AUTOSAR XML (schema 4-2-2)
package /UAES/ASW
  swc implementation Implementation: programming-language=C, sw-version=1.226.1, used-code-generator=Embedded Coder 7.1 (R2018b) 24-May-2018, vendor-id=0, behavior=InternalBehavior
    code-descriptors:
      code Code
        artifact-descriptors:
          short-label=Win_SLC_c, category=SWSRC
          short-label=Win_SLC_h, category=SWHDR
          short-label=rtwtypes_h, category=SWHDR
    resource consumption RsrcCons_Win_SLC
package /UAES/ASW/SwComponentTypes
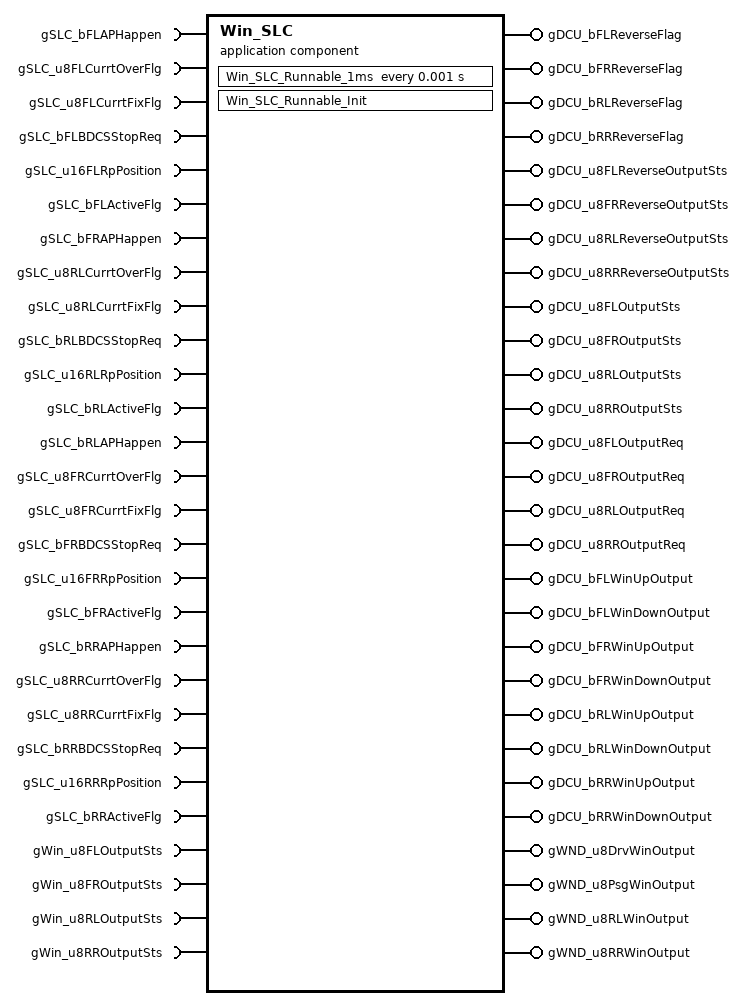
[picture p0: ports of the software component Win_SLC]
  application sw component type Win_SLC
    28 x require port:
      gSLC_bFLAPHappen: nonqueued-receiver-com-spec{data-element=gSLC_bFLAPHappen/Val, init-value=0}, required-interface=gSLC_bFLAPHappen
      gSLC_u8FLCurrtOverFlg: nonqueued-receiver-com-spec{data-element=gSLC_u8FLCurrtOverFlg/Val, init-value=0}, required-interface=gSLC_u8FLCurrtOverFlg
      gSLC_u8FLCurrtFixFlg: nonqueued-receiver-com-spec{data-element=gSLC_u8FLCurrtFixFlg/Val, init-value=0}, required-interface=gSLC_u8FLCurrtFixFlg
      gSLC_bFLBDCSStopReq: nonqueued-receiver-com-spec{data-element=gSLC_bFLBDCSStopReq/Val, init-value=0}, required-interface=gSLC_bFLBDCSStopReq
      gSLC_u16FLRpPosition: nonqueued-receiver-com-spec{data-element=gSLC_u16FLRpPosition/Val, init-value=0}, required-interface=gSLC_u16FLRpPosition
      gSLC_bFLActiveFlg: nonqueued-receiver-com-spec{data-element=gSLC_bFLActiveFlg/Val, init-value=0}, required-interface=gSLC_bFLActiveFlg
      gSLC_bFRAPHappen: nonqueued-receiver-com-spec{data-element=gSLC_bFRAPHappen/Val, init-value=0}, required-interface=gSLC_bFRAPHappen
      gSLC_u8RLCurrtOverFlg: nonqueued-receiver-com-spec{data-element=gSLC_u8RLCurrtOverFlg/Val, init-value=0}, required-interface=gSLC_u8RLCurrtOverFlg
      gSLC_u8RLCurrtFixFlg: nonqueued-receiver-com-spec{data-element=gSLC_u8RLCurrtFixFlg/Val, init-value=0}, required-interface=gSLC_u8RLCurrtFixFlg
      gSLC_bRLBDCSStopReq: nonqueued-receiver-com-spec{data-element=gSLC_bRLBDCSStopReq/Val, init-value=0}, required-interface=gSLC_bRLBDCSStopReq
      gSLC_u16RLRpPosition: nonqueued-receiver-com-spec{data-element=gSLC_u16RLRpPosition/Val, init-value=0}, required-interface=gSLC_u16RLRpPosition
      gSLC_bRLActiveFlg: nonqueued-receiver-com-spec{data-element=gSLC_bRLActiveFlg/Val, init-value=0}, required-interface=gSLC_bRLActiveFlg
      gSLC_bRLAPHappen: nonqueued-receiver-com-spec{data-element=gSLC_bRLAPHappen/Val, init-value=0}, required-interface=gSLC_bRLAPHappen
      gSLC_u8FRCurrtOverFlg: nonqueued-receiver-com-spec{data-element=gSLC_u8FRCurrtOverFlg/Val, init-value=0}, required-interface=gSLC_u8FRCurrtOverFlg
      gSLC_u8FRCurrtFixFlg: nonqueued-receiver-com-spec{data-element=gSLC_u8FRCurrtFixFlg/Val, init-value=0}, required-interface=gSLC_u8FRCurrtFixFlg
      gSLC_bFRBDCSStopReq: nonqueued-receiver-com-spec{data-element=gSLC_bFRBDCSStopReq/Val, init-value=0}, required-interface=gSLC_bFRBDCSStopReq
      gSLC_u16FRRpPosition: nonqueued-receiver-com-spec{data-element=gSLC_u16FRRpPosition/Val, init-value=0}, required-interface=gSLC_u16FRRpPosition
      gSLC_bFRActiveFlg: nonqueued-receiver-com-spec{data-element=gSLC_bFRActiveFlg/Val, init-value=0}, required-interface=gSLC_bFRActiveFlg
      gSLC_bRRAPHappen: nonqueued-receiver-com-spec{data-element=gSLC_bRRAPHappen/Val, init-value=0}, required-interface=gSLC_bRRAPHappen
      gSLC_u8RRCurrtOverFlg: nonqueued-receiver-com-spec{data-element=gSLC_u8RRCurrtOverFlg/Val, init-value=0}, required-interface=gSLC_u8RRCurrtOverFlg
      gSLC_u8RRCurrtFixFlg: nonqueued-receiver-com-spec{data-element=gSLC_u8RRCurrtFixFlg/Val, init-value=0}, required-interface=gSLC_u8RRCurrtFixFlg
      gSLC_bRRBDCSStopReq: nonqueued-receiver-com-spec{data-element=gSLC_bRRBDCSStopReq/Val, init-value=0}, required-interface=gSLC_bRRBDCSStopReq
      gSLC_u16RRRpPosition: nonqueued-receiver-com-spec{data-element=gSLC_u16RRRpPosition/Val, init-value=0}, required-interface=gSLC_u16RRRpPosition
      gSLC_bRRActiveFlg: nonqueued-receiver-com-spec{data-element=gSLC_bRRActiveFlg/Val, init-value=0}, required-interface=gSLC_bRRActiveFlg
      gWin_u8FLOutputSts: nonqueued-receiver-com-spec{data-element=gWin_u8FLOutputSts/Val, init-value=0}, required-interface=gWin_u8FLOutputSts
      gWin_u8FROutputSts: nonqueued-receiver-com-spec{data-element=gWin_u8FROutputSts/Val, init-value=0}, required-interface=gWin_u8FROutputSts
      gWin_u8RLOutputSts: nonqueued-receiver-com-spec{data-element=gWin_u8RLOutputSts/Val, init-value=0}, required-interface=gWin_u8RLOutputSts
      gWin_u8RROutputSts: nonqueued-receiver-com-spec{data-element=gWin_u8RROutputSts/Val, init-value=0}, required-interface=gWin_u8RROutputSts
    28 x provide port:
      gDCU_bFLReverseFlag: nonqueued-sender-com-spec{data-element=gDCU_bFLReverseFlag/Val, init-value=0}, provided-interface=gDCU_bFLReverseFlag
      gDCU_bFRReverseFlag: nonqueued-sender-com-spec{data-element=gDCU_bFRReverseFlag/Val, init-value=0}, provided-interface=gDCU_bFRReverseFlag
      gDCU_bRLReverseFlag: nonqueued-sender-com-spec{data-element=gDCU_bRLReverseFlag/Val, init-value=0}, provided-interface=gDCU_bRLReverseFlag
      gDCU_bRRReverseFlag: nonqueued-sender-com-spec{data-element=gDCU_bRRReverseFlag/Val, init-value=0}, provided-interface=gDCU_bRRReverseFlag
      gDCU_u8FLReverseOutputSts: nonqueued-sender-com-spec{data-element=gDCU_u8FLReverseOutputSts/Val, init-value=0}, provided-interface=gDCU_u8FLReverseOutputSts
      gDCU_u8FRReverseOutputSts: nonqueued-sender-com-spec{data-element=gDCU_u8FRReverseOutputSts/Val, init-value=0}, provided-interface=gDCU_u8FRReverseOutputSts
      gDCU_u8RLReverseOutputSts: nonqueued-sender-com-spec{data-element=gDCU_u8RLReverseOutputSts/Val, init-value=0}, provided-interface=gDCU_u8RLReverseOutputSts
      gDCU_u8RRReverseOutputSts: nonqueued-sender-com-spec{data-element=gDCU_u8RRReverseOutputSts/Val, init-value=0}, provided-interface=gDCU_u8RRReverseOutputSts
      gDCU_u8FLOutputSts: nonqueued-sender-com-spec{data-element=gDCU_u8FLOutputSts/Val, init-value=0}, provided-interface=gDCU_u8FLOutputSts
      gDCU_u8FROutputSts: nonqueued-sender-com-spec{data-element=gDCU_u8FROutputSts/Val, init-value=0}, provided-interface=gDCU_u8FROutputSts
      gDCU_u8RLOutputSts: nonqueued-sender-com-spec{data-element=gDCU_u8RLOutputSts/Val, init-value=0}, provided-interface=gDCU_u8RLOutputSts
      gDCU_u8RROutputSts: nonqueued-sender-com-spec{data-element=gDCU_u8RROutputSts/Val, init-value=0}, provided-interface=gDCU_u8RROutputSts
      gDCU_u8FLOutputReq: nonqueued-sender-com-spec{data-element=gDCU_u8FLOutputReq/Val, init-value=0}, provided-interface=gDCU_u8FLOutputReq
      gDCU_u8FROutputReq: nonqueued-sender-com-spec{data-element=gDCU_u8FROutputReq/Val, init-value=0}, provided-interface=gDCU_u8FROutputReq
      gDCU_u8RLOutputReq: nonqueued-sender-com-spec{data-element=gDCU_u8RLOutputReq/Val, init-value=0}, provided-interface=gDCU_u8RLOutputReq
      gDCU_u8RROutputReq: nonqueued-sender-com-spec{data-element=gDCU_u8RROutputReq/Val, init-value=0}, provided-interface=gDCU_u8RROutputReq
      gDCU_bFLWinUpOutput: nonqueued-sender-com-spec{data-element=gDCU_bFLWinUpOutput/Val, init-value=0}, provided-interface=gDCU_bFLWinUpOutput
      gDCU_bFLWinDownOutput: nonqueued-sender-com-spec{data-element=gDCU_bFLWinDownOutput/Val, init-value=0}, provided-interface=gDCU_bFLWinDownOutput
      gDCU_bFRWinUpOutput: nonqueued-sender-com-spec{data-element=gDCU_bFRWinUpOutput/Val, init-value=0}, provided-interface=gDCU_bFRWinUpOutput
      gDCU_bFRWinDownOutput: nonqueued-sender-com-spec{data-element=gDCU_bFRWinDownOutput/Val, init-value=0}, provided-interface=gDCU_bFRWinDownOutput
      gDCU_bRLWinUpOutput: nonqueued-sender-com-spec{data-element=gDCU_bRLWinUpOutput/Val, init-value=0}, provided-interface=gDCU_bRLWinUpOutput
      gDCU_bRLWinDownOutput: nonqueued-sender-com-spec{data-element=gDCU_bRLWinDownOutput/Val, init-value=0}, provided-interface=gDCU_bRLWinDownOutput
      gDCU_bRRWinUpOutput: nonqueued-sender-com-spec{data-element=gDCU_bRRWinUpOutput/Val, init-value=0}, provided-interface=gDCU_bRRWinUpOutput
      gDCU_bRRWinDownOutput: nonqueued-sender-com-spec{data-element=gDCU_bRRWinDownOutput/Val, init-value=0}, provided-interface=gDCU_bRRWinDownOutput
      gWND_u8DrvWinOutput: nonqueued-sender-com-spec{data-element=gWND_u8DrvWinOutput/Val, init-value=0}, provided-interface=gWND_u8DrvWinOutput
      gWND_u8PsgWinOutput: nonqueued-sender-com-spec{data-element=gWND_u8PsgWinOutput/Val, init-value=0}, provided-interface=gWND_u8PsgWinOutput
      gWND_u8RLWinOutput: nonqueued-sender-com-spec{data-element=gWND_u8RLWinOutput/Val, init-value=0}, provided-interface=gWND_u8RLWinOutput
      gWND_u8RRWinOutput: nonqueued-sender-com-spec{data-element=gWND_u8RRWinOutput/Val, init-value=0}, provided-interface=gWND_u8RRWinOutput
    behavior InternalBehavior: handle-termination-and-restart=NO-SUPPORT
      init event Win_SLC_InitEvent: start-on-event=Win_SLC_Runnable_Init
      timing event TMT_Win_SLC_Runnable_1ms: start-on-event=Win_SLC_Runnable_1ms, period=0.001
      runnable Win_SLC_Runnable_Init
      runnable Win_SLC_Runnable_1ms
        data-receive-point-by-arguments:
          28 x access:
            IN_gSLC_bFLAPHappen_Val: accessed-variable=gSLC_bFLAPHappen.Val
            IN_gSLC_bFLActiveFlg_Val: accessed-variable=gSLC_bFLActiveFlg.Val
            IN_gSLC_bFLBDCSStopReq_Val: accessed-variable=gSLC_bFLBDCSStopReq.Val
            IN_gSLC_bFRAPHappen_Val: accessed-variable=gSLC_bFRAPHappen.Val
            IN_gSLC_bFRActiveFlg_Val: accessed-variable=gSLC_bFRActiveFlg.Val
            IN_gSLC_bFRBDCSStopReq_Val: accessed-variable=gSLC_bFRBDCSStopReq.Val
            IN_gSLC_bRLAPHappen_Val: accessed-variable=gSLC_bRLAPHappen.Val
            IN_gSLC_bRLActiveFlg_Val: accessed-variable=gSLC_bRLActiveFlg.Val
            IN_gSLC_bRLBDCSStopReq_Val: accessed-variable=gSLC_bRLBDCSStopReq.Val
            IN_gSLC_bRRAPHappen_Val: accessed-variable=gSLC_bRRAPHappen.Val
            IN_gSLC_bRRActiveFlg_Val: accessed-variable=gSLC_bRRActiveFlg.Val
            IN_gSLC_bRRBDCSStopReq_Val: accessed-variable=gSLC_bRRBDCSStopReq.Val
            IN_gSLC_u16FLRpPosition_Val: accessed-variable=gSLC_u16FLRpPosition.Val
            IN_gSLC_u16FRRpPosition_Val: accessed-variable=gSLC_u16FRRpPosition.Val
            IN_gSLC_u16RLRpPosition_Val: accessed-variable=gSLC_u16RLRpPosition.Val
            IN_gSLC_u16RRRpPosition_Val: accessed-variable=gSLC_u16RRRpPosition.Val
            IN_gSLC_u8FLCurrtFixFlg_Val: accessed-variable=gSLC_u8FLCurrtFixFlg.Val
            IN_gSLC_u8FLCurrtOverFlg_Val: accessed-variable=gSLC_u8FLCurrtOverFlg.Val
            IN_gSLC_u8FRCurrtFixFlg_Val: accessed-variable=gSLC_u8FRCurrtFixFlg.Val
            IN_gSLC_u8FRCurrtOverFlg_Val: accessed-variable=gSLC_u8FRCurrtOverFlg.Val
            IN_gSLC_u8RLCurrtFixFlg_Val: accessed-variable=gSLC_u8RLCurrtFixFlg.Val
            IN_gSLC_u8RLCurrtOverFlg_Val: accessed-variable=gSLC_u8RLCurrtOverFlg.Val
            IN_gSLC_u8RRCurrtFixFlg_Val: accessed-variable=gSLC_u8RRCurrtFixFlg.Val
            IN_gSLC_u8RRCurrtOverFlg_Val: accessed-variable=gSLC_u8RRCurrtOverFlg.Val
            IN_gWin_u8FLOutputSts_Val: accessed-variable=gWin_u8FLOutputSts.Val
            IN_gWin_u8FROutputSts_Val: accessed-variable=gWin_u8FROutputSts.Val
            IN_gWin_u8RLOutputSts_Val: accessed-variable=gWin_u8RLOutputSts.Val
            IN_gWin_u8RROutputSts_Val: accessed-variable=gWin_u8RROutputSts.Val
        data-send-points:
          28 x access:
            OUT_gDCU_bFLReverseFlag_Val: accessed-variable=gDCU_bFLReverseFlag.Val
            OUT_gDCU_bFRReverseFlag_Val: accessed-variable=gDCU_bFRReverseFlag.Val
            OUT_gDCU_bRLReverseFlag_Val: accessed-variable=gDCU_bRLReverseFlag.Val
            OUT_gDCU_bRRReverseFlag_Val: accessed-variable=gDCU_bRRReverseFlag.Val
            OUT_gDCU_u8FLReverseOutputSts_Val: accessed-variable=gDCU_u8FLReverseOutputSts.Val
            OUT_gDCU_u8FRReverseOutputSts_Val: accessed-variable=gDCU_u8FRReverseOutputSts.Val
            OUT_gDCU_u8RLReverseOutputSts_Val: accessed-variable=gDCU_u8RLReverseOutputSts.Val
            OUT_gDCU_u8RRReverseOutputSts_Val: accessed-variable=gDCU_u8RRReverseOutputSts.Val
            OUT_gDCU_u8FLOutputSts_Val: accessed-variable=gDCU_u8FLOutputSts.Val
            OUT_gDCU_u8FROutputSts_Val: accessed-variable=gDCU_u8FROutputSts.Val
            OUT_gDCU_u8RLOutputSts_Val: accessed-variable=gDCU_u8RLOutputSts.Val
            OUT_gDCU_u8RROutputSts_Val: accessed-variable=gDCU_u8RROutputSts.Val
            OUT_gDCU_u8FLOutputReq_Val: accessed-variable=gDCU_u8FLOutputReq.Val
            OUT_gDCU_u8FROutputReq_Val: accessed-variable=gDCU_u8FROutputReq.Val
            OUT_gDCU_u8RLOutputReq_Val: accessed-variable=gDCU_u8RLOutputReq.Val
            OUT_gDCU_u8RROutputReq_Val: accessed-variable=gDCU_u8RROutputReq.Val
            OUT_gDCU_bFLWinUpOutput_Val: accessed-variable=gDCU_bFLWinUpOutput.Val
            OUT_gDCU_bFLWinDownOutput_Val: accessed-variable=gDCU_bFLWinDownOutput.Val
            OUT_gDCU_bFRWinUpOutput_Val: accessed-variable=gDCU_bFRWinUpOutput.Val
            OUT_gDCU_bFRWinDownOutput_Val: accessed-variable=gDCU_bFRWinDownOutput.Val
            OUT_gDCU_bRLWinUpOutput_Val: accessed-variable=gDCU_bRLWinUpOutput.Val
            OUT_gDCU_bRLWinDownOutput_Val: accessed-variable=gDCU_bRLWinDownOutput.Val
            OUT_gDCU_bRRWinUpOutput_Val: accessed-variable=gDCU_bRRWinUpOutput.Val
            OUT_gDCU_bRRWinDownOutput_Val: accessed-variable=gDCU_bRRWinDownOutput.Val
            OUT_gWND_u8DrvWinOutput_Val: accessed-variable=gWND_u8DrvWinOutput.Val
            OUT_gWND_u8PsgWinOutput_Val: accessed-variable=gWND_u8PsgWinOutput.Val
            OUT_gWND_u8RLWinOutput_Val: accessed-variable=gWND_u8RLWinOutput.Val
            OUT_gWND_u8RRWinOutput_Val: accessed-variable=gWND_u8RRWinOutput.Val
package /UAES/ASW/PortInterfaces
  56 x sender receiver interface:
    gSLC_bFLAPHappen
      data Val: category=VALUE, sw-calibration-access=READ-ONLY, type=boolean
    gSLC_u8FLCurrtOverFlg
      data Val: category=VALUE, sw-calibration-access=READ-ONLY, type=uint8
    gSLC_u8FLCurrtFixFlg
      data Val: category=VALUE, sw-calibration-access=READ-ONLY, type=uint8
    gSLC_bFLBDCSStopReq
      data Val: category=VALUE, sw-calibration-access=READ-ONLY, type=boolean
    gSLC_u16FLRpPosition
      data Val: category=VALUE, sw-calibration-access=READ-ONLY, type=uint16
    gSLC_bFLActiveFlg
      data Val: category=VALUE, sw-calibration-access=READ-ONLY, type=boolean
    gSLC_bFRAPHappen
      data Val: category=VALUE, sw-calibration-access=READ-ONLY, type=boolean
    gSLC_u8RLCurrtOverFlg
      data Val: category=VALUE, sw-calibration-access=READ-ONLY, type=uint8
    gSLC_u8RLCurrtFixFlg
      data Val: category=VALUE, sw-calibration-access=READ-ONLY, type=uint8
    gSLC_bRLBDCSStopReq
      data Val: category=VALUE, sw-calibration-access=READ-ONLY, type=boolean
    gSLC_u16RLRpPosition
      data Val: category=VALUE, sw-calibration-access=READ-ONLY, type=uint16
    gSLC_bRLActiveFlg
      data Val: category=VALUE, sw-calibration-access=READ-ONLY, type=boolean
    gSLC_bRLAPHappen
      data Val: category=VALUE, sw-calibration-access=READ-ONLY, type=boolean
    gSLC_u8FRCurrtOverFlg
      data Val: category=VALUE, sw-calibration-access=READ-ONLY, type=uint8
    gSLC_u8FRCurrtFixFlg
      data Val: category=VALUE, sw-calibration-access=READ-ONLY, type=uint8
    gSLC_bFRBDCSStopReq
      data Val: category=VALUE, sw-calibration-access=READ-ONLY, type=boolean
    gSLC_u16FRRpPosition
      data Val: category=VALUE, sw-calibration-access=READ-ONLY, type=uint16
    gSLC_bFRActiveFlg
      data Val: category=VALUE, sw-calibration-access=READ-ONLY, type=boolean
    gSLC_bRRAPHappen
      data Val: category=VALUE, sw-calibration-access=READ-ONLY, type=boolean
    gSLC_u8RRCurrtOverFlg
      data Val: category=VALUE, sw-calibration-access=READ-ONLY, type=uint8
    gSLC_u8RRCurrtFixFlg
      data Val: category=VALUE, sw-calibration-access=READ-ONLY, type=uint8
    gSLC_bRRBDCSStopReq
      data Val: category=VALUE, sw-calibration-access=READ-ONLY, type=boolean
    gSLC_u16RRRpPosition
      data Val: category=VALUE, sw-calibration-access=READ-ONLY, type=uint16
    gSLC_bRRActiveFlg
      data Val: category=VALUE, sw-calibration-access=READ-ONLY, type=boolean
    gWin_u8FLOutputSts
      data Val: category=VALUE, sw-calibration-access=READ-ONLY, type=uint8
    gWin_u8FROutputSts
      data Val: category=VALUE, sw-calibration-access=READ-ONLY, type=uint8
    gWin_u8RLOutputSts
      data Val: category=VALUE, sw-calibration-access=READ-ONLY, type=uint8
    gWin_u8RROutputSts
      data Val: category=VALUE, sw-calibration-access=READ-ONLY, type=uint8
    gDCU_bFLReverseFlag
      data Val: category=VALUE, sw-calibration-access=READ-ONLY, type=boolean
    gDCU_bFRReverseFlag
      data Val: category=VALUE, sw-calibration-access=READ-ONLY, type=boolean
    gDCU_bRLReverseFlag
      data Val: category=VALUE, sw-calibration-access=READ-ONLY, type=boolean
    gDCU_bRRReverseFlag
      data Val: category=VALUE, sw-calibration-access=READ-ONLY, type=boolean
    gDCU_u8FLReverseOutputSts
      data Val: category=VALUE, sw-calibration-access=READ-ONLY, type=uint8
    gDCU_u8FRReverseOutputSts
      data Val: category=VALUE, sw-calibration-access=READ-ONLY, type=uint8
    gDCU_u8RLReverseOutputSts
      data Val: category=VALUE, sw-calibration-access=READ-ONLY, type=uint8
    gDCU_u8RRReverseOutputSts
      data Val: category=VALUE, sw-calibration-access=READ-ONLY, type=uint8
    gDCU_u8FLOutputSts
      data Val: category=VALUE, sw-calibration-access=READ-ONLY, type=uint8
    gDCU_u8FROutputSts
      data Val: category=VALUE, sw-calibration-access=READ-ONLY, type=uint8
    gDCU_u8RLOutputSts
      data Val: category=VALUE, sw-calibration-access=READ-ONLY, type=uint8
    gDCU_u8RROutputSts
      data Val: category=VALUE, sw-calibration-access=READ-ONLY, type=uint8
    gDCU_u8FLOutputReq
      data Val: category=VALUE, sw-calibration-access=READ-ONLY, type=uint8
    gDCU_u8FROutputReq
      data Val: category=VALUE, sw-calibration-access=READ-ONLY, type=uint8
    gDCU_u8RLOutputReq
      data Val: category=VALUE, sw-calibration-access=READ-ONLY, type=uint8
    gDCU_u8RROutputReq
      data Val: category=VALUE, sw-calibration-access=READ-ONLY, type=uint8
    gDCU_bFLWinUpOutput
      data Val: category=VALUE, sw-calibration-access=READ-ONLY, type=boolean
    gDCU_bFLWinDownOutput
      data Val: category=VALUE, sw-calibration-access=READ-ONLY, type=boolean
    gDCU_bFRWinUpOutput
      data Val: category=VALUE, sw-calibration-access=READ-ONLY, type=boolean
    gDCU_bFRWinDownOutput
      data Val: category=VALUE, sw-calibration-access=READ-ONLY, type=boolean
    gDCU_bRLWinUpOutput
      data Val: category=VALUE, sw-calibration-access=READ-ONLY, type=boolean
    gDCU_bRLWinDownOutput
      data Val: category=VALUE, sw-calibration-access=READ-ONLY, type=boolean
    gDCU_bRRWinUpOutput
      data Val: category=VALUE, sw-calibration-access=READ-ONLY, type=boolean
    gDCU_bRRWinDownOutput
      data Val: category=VALUE, sw-calibration-access=READ-ONLY, type=boolean
    gWND_u8DrvWinOutput
      data Val: category=VALUE, sw-calibration-access=READ-ONLY, type=uint8
    gWND_u8PsgWinOutput
      data Val: category=VALUE, sw-calibration-access=READ-ONLY, type=uint8
    gWND_u8RLWinOutput
      data Val: category=VALUE, sw-calibration-access=READ-ONLY, type=uint8
    gWND_u8RRWinOutput
      data Val: category=VALUE, sw-calibration-access=READ-ONLY, type=uint8
